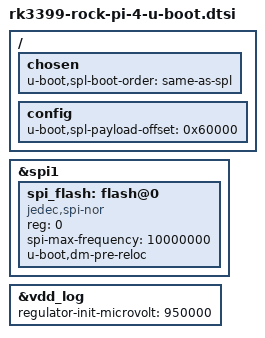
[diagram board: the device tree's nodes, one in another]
// SPDX-License-Identifier: GPL-2.0+
/*
 * Copyright (C) 2019 Jagan Teki <jagan@amarulasolutions.com>
 */

#include "rk3399-u-boot.dtsi"
#include "rk3399-sdram-lpddr4-100.dtsi"

/ {
	chosen {
		u-boot,spl-boot-order = "same-as-spl", &spi_flash, &sdmmc, &sdhci;
	};

	config {
		u-boot,spl-payload-offset = <0x60000>; /* @ 384KB */
	};
};

&spi1 {
	status = "okay";

	flash@0 {
		compatible = "jedec,spi-nor";
		reg = <0>;
		spi-max-frequency = <10000000>;
	};
};

&spi1 {
	spi_flash: flash@0 {
		u-boot,dm-pre-reloc;
	};
};

&vdd_log {
	regulator-init-microvolt = <950000>;
};
